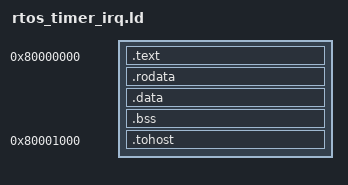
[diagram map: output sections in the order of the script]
OUTPUT_ARCH(riscv)
ENTRY(_start)

SECTIONS
{
    . = 0x80000000;
    .text : { *(.text.init) *(.text*) }
    .rodata : { *(.rodata*) }
    .data : { *(.data*) }
    .bss : { *(.bss*) *(COMMON) }
    .tohost 0x80001000 : { *(.tohost) }
}
